# Polarfire SoC register map
Vendor: Microchip; File version: 1.0
CPU: Microchip PolarFire SoC 1.0, little endian
Registers are 32-bit, read-write, reset 0x0 unless marked. A register's access mark holds for its fields unless they carry their own. Offsets are from the block's base; [hi:lo] are bit positions; {n}, {i} and the like mark numbered series.

## EMMC_SD (part 1 of 2) — EMMC_SD Controller
Base 0x20008000
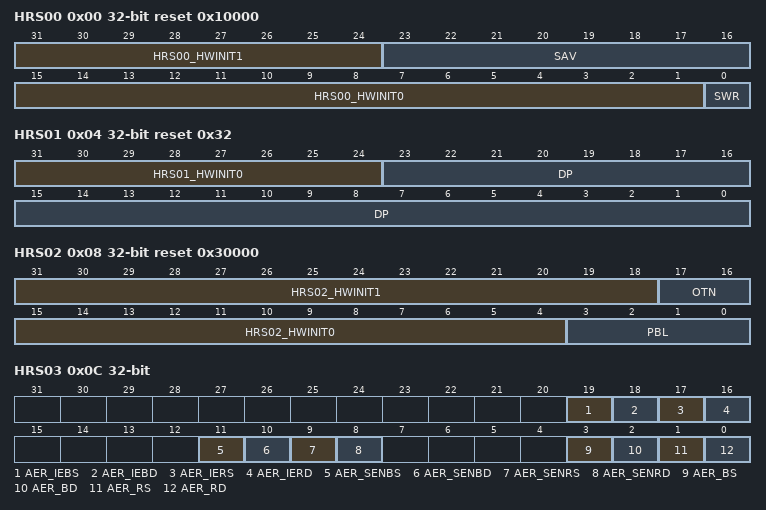
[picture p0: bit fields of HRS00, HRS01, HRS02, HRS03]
0x00 HRS00 reset 0x10000 — HRS00 - General Information Register
  [31:24] HRS00_HWINIT1 ro — HWINIT field
  [23:16] SAV ro — SAV - Slot Available This field provides a number of implemented slots. Each bit of the field is assigned to one of the slots (slot 0 is assigned to bit 16 of HRS00 register, slot 1 to bit 17, etc.). If given slot is implemented, the bit is read as 1. Otherwise, if given slot in unavailable, corresponding bit is 0. The slot 0 is always available. If slot n is implemented, the slot n-1 also is implemented. This configuration supports one slot and this field is equal to 0x01 (although the value can be altered by changing HWINIT_HRS00 value). HWINIT Field - Note this field is hardware initialized after reset and the value read back will match the IP configuration.
  [15:1] HRS00_HWINIT0 ro — HWINIT field
  [0] SWR — SWR - Software Reset When set to 1, the entire core is reset. After reset operation complete, SWR bit is automatically cleared. It takes some time to complete the requested reset operation, so the software should always poll SWR bit status, and continue the other operations only when SWR is cleared to 0. There is no difference between SWR and SRS11.SRFA software resets. Both resets the same flip-flops.
0x04 HRS01 reset 0x32 — HRS01 - Debounce Setting Register
  [31:24] HRS01_HWINIT0 ro — HWINIT field
  [23:0] DP — DP - Debounce Period Defines the number of system (clk) clock cycles used by the debounce logic, which detects card insertion and removal events. The debounce period is equal to DP * tclk, where tclk is the period of clk clock. If there is no change on s#_sdcd_n signal level for a programmed debounce period, the core logic decodes the card state as stable and triggers card_inserted or card_removed event. Typically, DP value should be chosen to obtain the period of 20ms. This register is reset to DEBOUNCE_PERIOD (HWINIT_HRS01) after reset.
0x08 HRS02 reset 0x30000 — HRS02 - Bus Setting Register
  [31:18] HRS02_HWINIT1 ro — HWINIT field
  [17:16] OTN — OTN - Number of Outstanding Transfers Specifies number of outstanding transfers on DMA (Master) interface. The number of outstadings is (OTN + 1), where OTN can be defined in range 0 to 3. This register is set to 3 after reset (i.e. 4 outstanding transfers) (HWINIT_HRS02).
  [15:4] HRS02_HWINIT0 ro — HWINIT field
  [3:0] PBL — PBL - Programmable Burst Length This field defines a maximum number of beats in DMA burst. The value can be changed when no active transfer. This register is 0 after reset. 0001b - 1 beat in burst 0010b - 2 beats in burst 0011b - 4 beats in burst 0100b - 8 bits in burst other - 16 beats in burst
0x0C HRS03 — HRS03 - AXI ERROR Responses Register These registers extend the standard set of SD-HOST interrupt statuses by information about AXI interface exceptions. The registers are divided into three groups: - Signal Enable registers allow to enable/mask signaling the Interrupt Status registers (HRS03[3:0]) on interrupt port - Status Enable registers allow to enable/disable interrupt source for each Interrupt Status separately - Interrupt Status are triggered whenever the interrupt source is detected and the Status Enable register is enabled
  [19] AER_IEBS — AER_IEBS - Signal Enable for AXI ERROR Response B channel: SLVERR 1 - interrupt enable 0 - interrupt masked
  [18] AER_IEBD — AER_IEBD - Signal Enable for AXI ERROR Response B channel: DECERR 1 - interrupt enable 0 - interrupt masked
  [17] AER_IERS — AER_IERS - Signal Enable for AXI ERROR Response R channel: SLVERR 1 - interrupt enable 0 - interrupt masked
  [16] AER_IERD — AER_IERD - Signal Enable for AXI ERROR Response R channel: DECERR 1 - interrupt enable 0 - interrupt masked
  [11] AER_SENBS — AER_SENBS - Status Enable for AXI ERROR Response B channel: SLVERR 1 - status enable 0 - status disable
  [10] AER_SENBD — AER_SENBD - Status Enable for AXI ERROR Response B channel: DECERR 1 - status enable 0 - status disable
  [9] AER_SENRS — AER_SENRS - Status Enable for AXI ERROR Response R channel: SLVERR 1 - status enable 0 - status disable
  [8] AER_SENRD — AER_SENRD - Status Enable for AXI ERROR Response R channel: DECERR 1 - status enable 0 - status disable
  [3] AER_BS — AER_BS - AXI ERROR Response B channel: SLVERR This bit is set when a SLVERR is detected on AXI Master bus in B channel (Write Response Channel).
  [2] AER_BD — AER_BD - AXI ERROR Response B channel: DECERR This bit is set when a DECERR is detected on AXI Master bus in B channel (Write Response Channel).
  [1] AER_RS — AER_RS - AXI ERROR Response R channel: SLVERR This bit is set when a SLVERR is detected on AXI Master bus in R channel (READ Response Channel).
  [0] AER_RD — AER_RD - AXI ERROR Response R channel: DECERR This bit is set when a DECERR is detected on AXI Master bus in R channel (READ Response Channel).
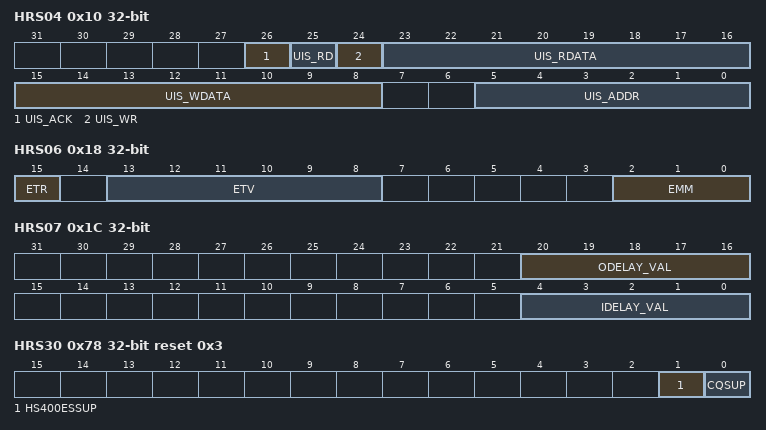
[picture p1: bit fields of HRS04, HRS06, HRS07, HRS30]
0x10 HRS04 — HRS04 - SD/eMMC PHY Registers Interface This register enables access to the SD/eMMC PHY registers. The interface behavior is described in section SD/eMMC PHY Register Intreface.
  [26] UIS_ACK ro — UIS_ACK - PHY Transaction Acknowledge This bit is set 1 when UIS_WR or UIS_RD is confirmed, so either read data is available in UIS_RDATA, or written data is already updated PHY register.
  [25] UIS_RD — UIS_RD - PHY Read Transaction Request This bit requests read transaction from PHY Register.
  [24] UIS_WR — UIS_WR - PHY Write Transaction Requests This bit requests write transaction to PHY Register.
  [23:16] UIS_RDATA ro — UIS_RDATA - PHY Read Data This field stories data read from PHY Register.
  [15:8] UIS_WDATA — UIS_WDATA - PHY Write Data This field stories data to be written to PHY Register.
  [5:0] UIS_ADDR — UIS_ADDR - PHY Register Address This filed stories address of PHY Register which is to be read of written. Refer to the Integration Manual (cdns_sd4hc_integration_manual.pdf), Table: Remapping register address to address of registers described in SD/eMMC PHY User Guide (cdns_sd_emmc_dll_phy_user_guide.pdf).
0x18 HRS06 — HRS06 - eMMC control registers
  [15] ETR — ETR - eMMC Tune Request Setting this bit 1, the tune value is updated by ETV. This bit is set 1 until the requested value is applied. The tuning command request is to be set after this bit is automatically clear to 0.
  [13:8] ETV — ETV - eMMC Tune Value This register contains value can update the tune value and in consequence sample point. The value become tune value when the ETR transits from 1 to 0.
  [2:0] EMM — EMM - eMMC Mode select This field sets eMMC mode. The mode should reflect to the eMMC device setting. If the SD card is in use, this field needs to be 0000b. 0000b - SD Card in use 0010b - SDR 0011b - DDR 0100b - HS200 0101b - HS400 0110b - HS400 Enhanced Strobe others - Legacy
0x1C HRS07 — HRS07 - IO Delay Information Register
  [20:16] ODELAY_VAL — ODELAY_VAL - Output delay value for IO. Designer should update this register with delay value of IO with appriopriate output delay. Delay is count in half of period of sdmclk. If sdmclk is working at 200MHz frequency, then 1 is 2,5 ns. This value will be used to compensate delay of DAT line when controller is READ WAIT. The sum value of IDELAY_VAL, ODELAY_VAL should be less equal 5'd20 for controller to work properly.
  [4:0] IDELAY_VAL — IDELAY_VAL - Input delay value for IO. Designer should update this register with delay value of IO with appriopriate input delay. Delay is count in half of period of sdmclk. If sdmclk is working at 200MHz frequency, then 1 is 2,5 ns. This value will be used to compensate delay of DAT line when controller is driving READ WAIT. The sum value of IDELAY_VAL, ODELAY_VAL should be less equal 5'd20 for controller to work properly.
0x78 HRS30 ro reset 0x3 — HRS30 - Host Capability Register This register states whether configurable options are available or are not available in the SD/eMMC Host Controller configuration. This register gives such information about features not been covered by the standard capability registers (SRS16-SRS18).
  [1] HS400ESSUP — High Speed 400 Enhance Strobe supported This field informs whether HS400 Enhance Strobe mode is supported (1) or is not supported (0).
  [0] CQSUP — Command Queuing supported This field informs whether Command Queuing is supported (1) or is not supported (0).
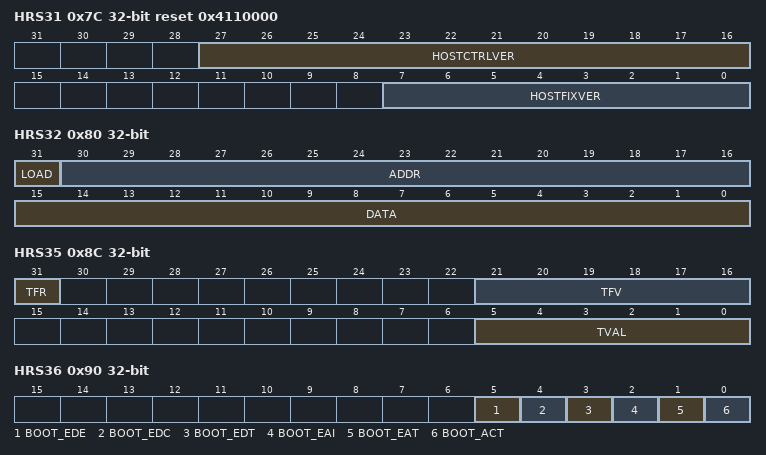
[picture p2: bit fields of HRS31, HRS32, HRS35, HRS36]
0x7C HRS31 ro reset 0x4110000 — HRS31 - Host Controller Version This register contains the host controller version number.
  [27:16] HOSTCTRLVER — Host Controller Version Release number of the Host Controller
  [7:0] HOSTFIXVER — Fix Version Number Number of the fix related to the Host Controller Version.
0x80 HRS32 — HRS32 - FSM Monitor Register
  [31] LOAD — LOAD - FSM monitor update request Setting this bit to 1 starts internal FSM monitor to load value from selected FSM. After finishing this bit will be automatically cleared by hardware and FSM status can be read.
  [30:16] ADDR — ADDR - FSM address This field selects which FSM status will be read. All available status machines are listed in Debug section of User Guide.
  [15:0] DATA ro — DATA - FSM status This register contains read FSM status. Before reading it user should select FSM address (ADDR), set LOAD bit and wait until hardware clears it.
0x84 HRS33 ro — HRS33 - Tune Status 0 Register
  [31:0] STAT0 — STAT0 - Tune status 0 After invoking UHS-I tunning procedure each bit of this register represents status of one tuning step. This field correspond to tuning steps 31-0. 0 - Step failed 1 - Step passed
0x88 HRS34 ro — HRS34 - Tune Status 1 Register
  [7:0] STAT1 — STAT1 - Tune status 1 This field is continuation of STAT0 field. Its value represents status of tuning steps 39-32.
0x8C HRS35 — HRS35 - Tune Debug Register
  [31] TFR — TFR - Tune Force Request Setting this bit 1, the tune value is updated by TFV. This bit is set 1 until the requested value is applied. The tuning command request is to be set after this bit is automatically clear to 0.
  [21:16] TFV — TFV - Tune Force Value This register contains value which can update the tune value and in consequence sample point. The new tune value becomes valid when the TFR transits from 1 to 0.
  [5:0] TVAL ro — TVAL - Tune Current Value This field represents selected value of UHS-I delay.
0x90 HRS36 ro — HRS36 - Boot Status Register
  [5] BOOT_EDE — Boot Error - End Bit Error
  [4] BOOT_EDC — Boot Error - Data CRC Error
  [3] BOOT_EDT — Boot Error - Data Timeout Error
  [2] BOOT_EAI — Boot Error - Invalid Acknowledge Error
  [1] BOOT_EAT — Boot Error - Acknowledge Timeout Error
  [0] BOOT_ACT — Boot Active Informs that the BOOT is active and the operation cannot be interfere by writing any registers.
0x94 HRS37 — HRS37 - Read block gap coefficient interface mode select
  [5:0] RGB_COEFF_IFM — RGB_COEFF_IFM - Read Block Gap Coefficient This register selects a target Read Block Coefficient. The Host Controller has a set of Read Block Coefficient registers. Each SD and eMMC speed mode has one dedicated register. While HRS38 is updated to set a Coefficient value, this register selects a target Read Block Coefficient. Following list shows the addresses to speed modes relation: 000000b - Default Speed (DS) 000001b - High Speed (HS) 001000b - UHS-I SDR12 001001b - UHS-I SDR25 001010b - UHS-I SDR50 001011b - UHS-I SDR104 001100b - UHS-I DDR50 100000b - eMMC Legacy 100001b - eMMC SDR 100010b - eMMC DDR 100011b - eMMC HS200 100100b - eMMC HS400 100101b - eMMC HS400 Enhanced Strobe
0x98 HRS38 — HRS38 - Read block gap coefficient
  [3:0] RGB_COEFF — Read block gap coefficient. Read block gap timing can be variable based on pad timing when the clock is stopped for flow control or stop at block gap purposes. When stopping the clock the host controller has default settings for each interface mode that ensures read block gap timing is met with pad delays up to 5ns (input and output path). If pad delays are longer than 5ns then the default settings can changed (increased) to ensure read block gap timing is not violated. HRS38 has a register for each interface mode and the interface mode is selected by using HRS38.
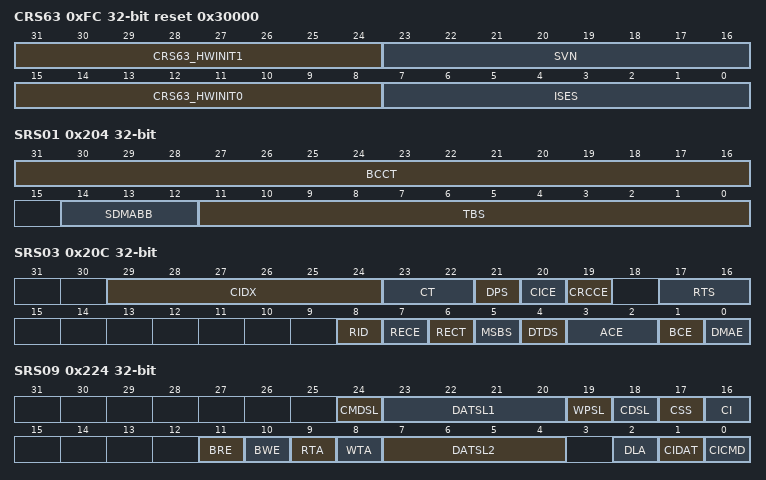
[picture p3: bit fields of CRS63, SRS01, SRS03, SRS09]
0xFC CRS63 ro reset 0x30000 — CRS63 - Host Controller Version/Slot Interrupt Status
  [31:24] CRS63_HWINIT1 — HWINIT field
  [23:16] SVN — SVN - Specification Version Number. This field identifies the Host Controller Specification Version. 0h - Version 1.00 1h - Version 2.00 2h - Version 3.00 3h - Version 4.00 4h-FFh - reserved The host is compatible with SD Host Specification Version 4.00. HWINIT Field - Note this field is hardware initialized after reset and the value read back will match the IP configuration.
  [15:8] CRS63_HWINIT0 — HWINIT field
  [7:0] ISES — ISES - Interrupt Signal For Each Slot. This field allows to determine which slot is currently signaling Interrupt/Wakeup signals. Each bit is logical OR of all Interrupts Signal and Wakeup Signal implemented in given slot. 0 - Slot 1 1 - Slot 2 ... 7 - Slot 8
0x200 SRS00 — SRS00 - SDMA System Address / Argument 2
  [31:0] SAAR — SAAR - System Address / Argument 2 This field is used as: - SDMA system memory address - Auto CMD23 Argument System Address: This register is used as base address when SDMA engine is selected (SRS03.DMAE=1 and SRS10.DMASEL=0) and SRS15.HV4E=0. When the SDMA has stopped at the SDMA block gap, writing to SAAR[31:24] resumes SDMA transfer. If the SDMA engine is stopped, value of the SAAR[31:24] register is set to the next contiguous system address of the next data position Auto CMD23 Argument: This mode is used when non-DMA or ADMA2 engine is selected or SRS15.HV4E=1. When the block count is enabled, software will set value from range 00000000h to 0000FFFFh.
0x204 SRS01 — SRS01 - Block Size / Block Count
  [31:16] BCCT — BCCT - Block Count For Current Transfer With this field, the number of data blocks can be defined for next transfer. This register is used when SRS03.BCE is set 1, otherwise it will be ignored. The value is decremented after each block transfer. When this field is set 0, no data blocks will be transferred. During data transfer read operation may return invalid value, and write operations are ignored. 0000h - no block transfer 0001h..FFFFh - 1..65535 block(s) transfer.
  [14:12] SDMABB — SDMABB - SDMA Buffer Boundary In this field, the system address boundary can be set for SDMA engine. The SDMA transfer stops crossing the address boundary and generates the DMA Interrupt (SRS12.DMAINT). After the DMA Interrupt, when the SRS15.HV4E is 0, the software should write new SDMA System Address (SRS00.SAAR / SRS22.DMASA1) in order to resume the SDMA transaction. 0 - 4k bytes address boundary 1 - 8k bytes address boundary 2 - 16k bytes address boundary 3 - 32k bytes address boundary 4 - 64k bytes address boundary 5 - 128k bytes address boundary 6 - 256k bytes address boundary 7 - 512k bytes address boundary
  [11:0] TBS — TBS - Transfer Block Size This field defines block size for block data transfers. During data transfer, read operations may return an invalid value, and write operations are ignored. The software will not set value that exceeds the physically implemented internal FIFO buffer size. The buffer size is equal to 2^FIFODEPTH, where FIFODEPTH is the generic parameter of the core. The SD/MMC (memory) uses block size up to 512 bytes. The SDIO can use up to 2048 bytes. 000h - not used 001h - 1 data block 002h - 2 data blocks 003h - 3 data blocks ... 1FFh - 511 data blocks 200h - 512 data blocks ... 800h - 2048 data blocks others - not used. Note: It is recommended for the software to use native data block size (512B) in case of multiple data block transfer (SRS03.MSBS==1). Using smaller block may cause unexpected response error when flow control is activated (i.e. SDCLK is disabled) during response transfer.
0x208 SRS02 — SRS02 - Argument 1
  [31:0] ARG1 — ARG1 - Command Argument 1 This field contains 32-bits argument for command issued by SRS03.CIDX file write.
0x20C SRS03 — SRS03 - Command/Transfer Mode
  [29:24] CIDX — CIDX - Command Index This field contains a command number (index) of the command to be sent. The index can be defined in range 00-63, which means all commands (CMD00-CMD63 and ACMD00-ACMD63) defined in related specifications are supported. Writing this filed triggers the actual command transfer. This field is to be written only when Command Inhibit CMD bit is 0 in Present State Register (SRS09.CICMD). To check the list of available commands, refer to the appropriate card/device specifications.
  [23:22] CT — CT - Command Type This field defines specific type of command. - Normal Command (0) - used by default when other command types are not intended to be used - Suspend Command (01b) - not used - Resume Command (10b) - not used - Abort Command (11b) - used when the software wants to stop the current data transfer (read or write data transfer). The read transfer ends by stopping transfer to the internal buffer. The write transfer ends with releasing DAT line to High-Z state. Then, after sending an Abort Command, the software will issue the software reset. The Suspend and Resume Mechanism is not supported by the SD Host version 4.00 and later, and the Suspend and Resume Commands will not be used.
    0=Normal; 1=Suspend; 2=Resume; 3=Abort
  [21] DPS — DPS - Data Present Select Set to 1 for commands which transfer data (i.e. read or write data using DAT line). Set to 0 for all other commands, including: - Commands using only CMD line - Commands with busy signalized on DAT[0] line (SRS03.RTS=11b)
  [20] CICE — CICE - Command Index Check Enable When set to 1, the host checks if the Command Index field in the response is equal to the SRS03.CIDX value. When 0, the check is not performed and Command Index field of the response is ignored. Recommended settings depends on response type, see following table for details: SRS03.RTS=00: 0 - No Response SRS03.RTS=01: 0 - R2 SRS03.RTS=10: 0 - R3, R4 SRS03.RTS=10: 1 - R1, R5, R6, R7 SRS03.RTS=11: 1 - R1b, R5b
  [19] CRCCE — CRCCE - Command CRC Check Enable When set to 1, the host checks if the CRC field of the response is valid. When 0, the CRC check is disabled and the CRC field of the response is ignored. The CRC check should be disabled for responses which do not contain an actual CRC value (some responses contain all 1s in place of the CRC field), and enabled for all other kinds of responses. Recommended settings depends on response type, see following table for details: SRS03.RTS=00: 0 - No Response SRS03.RTS=01: 0 - R2 SRS03.RTS=10: 0 - R3, R4 SRS03.RTS=10: 1 - R1, R5, R6, R7 SRS03.RTS=11: 1 - R1b, R5b
  [17:16] RTS — RTS - Response Type Select Defines the expected response length. 00b - no response 01b - 136-bit response 10b - 48-bit response 11b - 48-bit response with BUSY Every command implies one of the response types listed above. To check the response type corresponding to a given command, please refer to the appropriate card/device specifications.
  [8] RID — RID - Response Interrupt Disable When set to 1, the Command Complete Interrupt (SRS12.CC) will be disabled. The host will ignore the SRS13.CC_SE and behave as the SRS13.CC_SE would be 0. When set to 0, the SRS12.CC will be enabled or disabled depend on the SRS13.CC_SE bit only.
  [7] RECE — RECE - Response Error Check Enable When set 1, the host will look after R1/R5 responses. If any error will be detected in the response, the SRS12.ERSP bit is set to 1. The software will set this bit only when R1/R5 response is expected. The software will set SRS03.RID and RECE bits to 1 when the host checks R1/R5 errors. And both bits will be clear to 0, when the Software Driver will checks R1/R5 errors. On response error, the SRS12.ERSP bit (in Interrupt Status) is set 1.
  [6] RECT — RECT - Response Type R1/R5 Select R1 or R5 response type for the response content checker. Listed below error bits will be evaluated. RECT = 0, Response Type - R1 (SD Memory): bit 31 OUT_OF_RANGE bit 30 ADDRESS_ERROR bit 29 BLOCK_LEN_ERROR bit 26 WP_VIOLATION bit 25 CARD_IS_LOCKED bit 23 COM_CRC_ERROR bit 21 CARD_ECC_FAILED bit 20 CC_ERROR bit 19 ERRORRECT = 1 RECT = 1, Response Type - R5 (SDIO): bit 7 COM_CRC_ERROR bit 3 ERROR bit 1 FUNCTION_NUMBER bit 0 OUT_OF_RANGE This field is ignored when SRS03.RECE=0.
  [5] MSBS — MSBS - Multi/Single Block Select Multi-block or single-block data transfer can be selected with this field. 0 - Single-block 1 - Multi-block This field is hardware-protected by Command Inhibit DAT bit in Present State Register (SRS09.CIDAT). When CIDAT=1, all writes to this field are ignored.
  [4] DTDS — DTDS - Data Transfer Direction Select Selects direction of data transfer for commands with DPS=1. 0 - Write 1 - Read For commands with SRS03.DPS=0, this field is ignored. This field is hardware-protected by Command Inhibit DAT bit in Present State Register (SRS09.CIDAT). When CIDAT=1, all writes to this field are ignored.
  [3:2] ACE — ACE - Auto CMD Enable The field allows to send one additional command to the card/device when the command is issued. 00b - No auto command 01b - Auto CMD12 10b - Auto CMD23 11b - Reserved If Auto CMD disable (00b) is set, the host does not send any additional command. This setting will be used when auto command is not required or not intended. If Auto CMD12 (01b) is set, the host sends CMD12 (Abort) automatically when last block of multi-block transfer is completed. If Auto CMD23 (10b) is set, the host sends CMD23 (Set Block Count) automatically before issued transfer data command. An argument of this command can be set in SRS00. On any error the issued command will not be sent. This field is hardware-protected by Command Inhibit DAT bit in Present State Register (SRS09.CIDAT). When SRS09.CIDAT=1, all writes to this field are ignored.
  [1] BCE — BCE - Block Count Enable When set to 1, the SRS01.BCCT Block Count is enabled. Each transferred block automatically decrements the counter value. The multi-block transfer will end, when the counter reaches 0. So the finite transfer can not be performed with this setting. When 0, block counting is disabled, and SRS01.BCCT retains its value. The transfer will be infinite in non-DMA and SDMA modes. For ADMA mode the transfer can be infinite or finite. The finite transfer ends on reading the descriptor with END status (so the transfer length is designated by the table of descriptors). In case of infinite transfer, the software will explicitly set ABORT command type to stop transfer. This field is hardware-protected by Command Inhibit DAT bit in Present State Register (SRS09.CIDAT). When CIDAT=1, all writes to this field are ignored.
  [0] DMAE — DMAE - DMA Enable When set to 1, it enables DMA functionality. DMA can be enabled only if it is supported as indicated in the DMA Support in the SRS16.DMAS register. If DMA is not supported (due to host configuration), this bit is ignored. This field is hardware-protected by Command Inhibit DAT bit in Present State Register (SRS09.CIDAT). When SRS09.CIDAT=1, all writes to this field are ignored. Note: The ADMA2 mode uses only the finite transfer mode, i.e. this bit is to be set 1.
0x210 SRS04 ro — The SRS04 - SRS07 registers store the response returned by the card. The mapping of the actual device response and the SRS04 - SRS07 contents depends on the type of response. The type of response is determined by the RTS field (Response Type) for all user-defined commands. The separate cases are the Auto-CMD12 response (called R1b in the SD Memory Specification) and Auto-CMD23 response (called R1 in the SD Memory Specification). Auto-CMD12 and Auto-CMD23 responses are handled by the core automatically and goes to the SRS07 register regardless of the RTS value. SRS04-SRS07 relation to received response field: Auto-CMD12 resp: Response field R[39:8] - RESP3[31:0] Auto-CMD23 resp: Response field R[39:8] - RESP3[31:0] No response: RTS=00b 136-bit: RTS=01b, Response field R[127:8] - {RESP3[23:0], RESP2[31:0], RESP1[31:0], RESP0[31:0]} 48-bit: RTS=10b, Response field R[39:8] - RESP1[31:0] 48-bit with BUSY: RTS=11b, Response field R[39:8] - RESP1[31:0] Implementation note: Registers value are undefined after reset, and will be valid after response is received.
  [31:0] RESP1 — RESP1 - Response Register #1
{0x200+4i} SRS{i:02} ro (i=5..7) — Described in SRS04.
  [31:0] RESP{i-3} — RESP{i-3} - Response Register #{i-3}
0x220 SRS08 — SRS08 - Data Buffer
  [31:0] BDP — BDP - Buffer Data Port The field is to access the internal buffer (data block) in non-DMA transfer mode. 8-bit, 16-bit, or 32-bit access to SRS08 is possible with the following restrictions: - Only sequential contiguous access in Little Endian mode is possible. For example, if the software accesses BDP[7:0], then the next transfer will access BDP[15:8]. No byte skipping is allowed. - Each new block will start at the least significant byte of BDP, which is BDP[7:0]. - If the block size is not a multiple of 32-bits, and the software accesses BDP using 32-bit words, then the excess bytes of the last word are ignored. This allows the software driver to use only 32-bit data transfers regardless of the block size. - Access to the register with precaution - the FIFO pointers can be damaged when buffer is not ready or when number of accesses exceed the transfer block size (SRS01.TBS ). Following shows all transfers (byte enable variations) that are allowed on SRS08: Transfer width = 32-bit: be[3:0] = 'b1111 -> BDP[31:0] Transfer width = 16-bit: be[3:0] = 'b0011 -> BDP[15:0] be[3:0] = 'b1100 -> BDP[31:16] Transfer width = 8-bit: be[3:0] = 'b0001 -> BDP[7:0] be[3:0] = 'b0010 -> BDP[15:8] be[3:0] = 'b0100 -> BDP[23:16] be[3:0] = 'b1000 -> BDP[31:24]
0x224 SRS09 ro — SRS09 - Present State Register
  [24] CMDSL — CMDSL - CMD Line Signal Level (SD Mode only) The value is equal to the actual signal level on CMD line of the SD interface (s#_cmd_i). Is useful for debugging purposes.
  [23:20] DATSL1 — DATSL1 - DAT[3:0] Line Signal Level (SD Mode only) The value is equal to the actual signal level on DAT pins of the SD interface: SRS09.23 - s#_dat_i[3] pin level SRS09.22 - s#_dat_i[2] pin level SRS09.21 - s#_dat_i[1] pin level SRS09.20 - s#_dat_i[0] pin level
  [19] WPSL — WPSL - Write Protect Switch Pin Level The value is equal to the actual signal level on Write Protect pin of the SD interface (sdwp_s#_n). 1 - means that the write operation is enabled 0 - means that the write operations is disabled
  [18] CDSL — CDSL - Card Detect Pin Level The value is equal to the inverted signal level on Card Detect pin of the SD interface (sdsl_s#_n). 1 - means that the card is inserted 0 - means no card is inside the slot Debouncing is not performed on CDSL, therefore the use of Card Inserted (CI) bit is recommended during normal work. CDSL bit is useful only for debugging purposes.
  [17] CSS — CSS - Card State Stable Indicates if Card Detect Pin Level (CDSL) is stable. 1 - means that the CDSL value is stable 0 - means that the CDSL is not stable (during card insertion/removal or during the reset) Field is useful for debugging purposes.
  [16] CI — CI - Card Inserted Indicates if the card is inserted inside the slot. 0 - no card in slot 1 - card is inserted Unlike SRS09.CDSL, value of SRS09.CI bit is guaranteed to be stable (i.e. debouncing is performed on this bit). Use of this bit is recommended during the normal operation of host.
  [11] BRE — BRE - Buffer Read Enable This field represents data buffer (SRS08.BDP) state for read transfer in non-DMA mode. 1 - valid data can be read from the data buffer 0 - no valid data inside the data buffer After reading the entire data block, this bit changes to 0.
  [10] BWE — BWE - Buffer Write Enable This bit represents data buffer (SRS08.BDP) state for write transfer in non-DMA mode. 1 - data can be written to the data buffer 0 - data cannot be written After reading the entire data block, this changes to 0. This bit will be cleared in case of SBGR at non-DMA write transfer (even if the internal buffer is ready). The buffer must not be written after the SBGR. If the BWR was set, the only action from the S/W is to clear the interrupt status.
  [9] RTA — RTA - Read Transfer Active (SD Mode only) Indicates the status of the read data transfer. 0 - no data read transfer in progress 1 - data read transfer in progress Bit is set 1 after sending the read command, or after restarting the read transfer by the Continue Request (SRS10.CREQ). Bit is set 0 by the hardware after the last block of the read transfer, or after stopping the read transfer by the Stop at Block Gap Request (SRS10.SBGR). In both cases, the entire data is to be read by the system from the internal data buffer before setting this bit to 0. In other words, SRS09.RTA=0 means that the entire data is already transferred to the system, and internal data buffer is empty.
  [8] WTA — WTA - Write Transfer Active (SD Mode only) Indicates the status of the write data transfer. 0 - no data write transfer in progress 1 - data write transfer in progress Bit is set 1 after sending the write command, or after restarting the write transfer by the Continue Request (SRS10.CREQ). Bit is set 0 by the hardware after the last block of the write transfer, or after stopping the write transfer by the Stop at Block Gap Request (SRS10.SBGR). In both cases, the entire data has to be transferred to the card from the internal data buffer before setting this bit to 0. In other words, WTA=0 means that the entire data is already transferred to the card, and CRC response for the last data block is already received.
  [7:4] DATSL2 — DATSL2 - DAT[7:4] Line Signal Level (SD Mode only) Field can be used to monitor DAT lines in range 7-4. The value is equal to the actual signal level on DAT pins of the SD interface: SFR9.7 - dat7_i_pin level SFR9.6 - dat6_i_pin level SFR9.5 - dat5_i_pin level SFR9.4 - dat4_i_pin level
  [2] DLA — DLA - DAT Line Active (SD Mode only) Indicates if the DAT lines of SD interface are currently in use. 1 - DAT lines are active (in use) 0 - DAT lines are released (not in use) This bit set to 1, when Read or Write Transfer bits are active (SRS09.RTA=1 or SRS09.WTA=1), or if the card indicates busy state on the DAT lines. The card can become busy immediately after the write operation, or after command which requires response with busy. Falling edge of this bit (change from 1 to 0) directly triggers Transfer Complete Interrupt (SRS12.TC).
  [1] CIDAT — CIDAT - Command Inhibit DAT (SD Mode only) Indicates if the host can issue a command which uses DAT line. Commands which use DAT line include write and read data commands and commands with busy response. 1 - command using DAT line cannot be sent 0 - command using DAT line can be sent When CIDAT=1 then the SRS03[15:0] is write-protected. The software can write SRS03[15:0] only when CIDAT=0.
  [0] CICMD — CICMD - Command Inhibit CMD Indicates if the host can issue a command. 0 - command can be sent 1 - command cannot be sent If this bit is 0, indicates the CMD line is not in use and the Host Controller can issue an SD command using the CMD line. This bit is set immediately after the CI is written, indicating start of command transmission. This bit is cleared when the command response is received. Even if the Command Inhibit DAT is set to 1, commands using only the CMD line can be issued if the Command Inhibit CMD is 0. Change from 1 to 0 directly triggers Command Complete Interrupt (SRS12.CC).
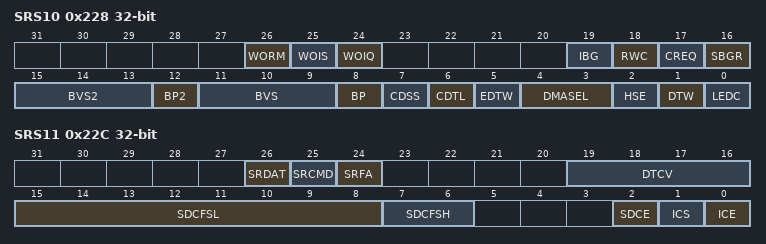
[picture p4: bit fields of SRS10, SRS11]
0x228 SRS10 — SRS10 - Host Control 1 (General / Power / Block-Gap / Wake-Up)
  [26] WORM — WORM - Wakeup Event Enable On SD Card Removal When set to 1, enables wake-up event via Card Removal assertion in the SRS12.CR register.
  [25] WOIS — WOIS - Wake-Up Event Enable On Card Inserted When set to 1, enables wake-up event via Card Insertion assertion in the SRS12.CIN register.
  [24] WOIQ — WOIQ - Wakeup Event Enable On Card Interrupt When set to 1, enables wake-up event via Card Interrupt assertion in the SRS12.CINT
  [19] IBG — IBG - Interrupt At Block Gap (SD Mode only) When set to 1, enables interrupt detection at the block gap for a multiple block transfer. This bit is valid only in SD4 mode. If the SD card cannot signal an interrupt during a multiple block transfer, this bit should be set to 0. This field is ignored in UHS-II mode.
  [18] RWC — RWC - Read-Wait Control (SD Mode only) When set to 1, enables Read Wait control. The Read Wait function is optional for SDIO cards. If the card does not support read wait, this bit would never be set to 1; otherwise, DAT line conflict may occur. This field is ignored in UHS-II mode.
  [17] CREQ — CR - Continue Request When set to 1, restarts the transfer previously stopped using the Stop At Block Gap. The software will set SRS10.SBGR (Stop At Block Gap) bit to 0 before setting the (CR) Continue Request. When SRS10.SBGR=1, then all write operations to Continue Request are ignored. Clearing SRS10.SBGR can be done before or simultaneously with writing the CR. Continue Request bit is cleared automatically by the host when SRS09.DLA (Dat Line Active) changes from 0 to 1, indicating the actual restart of the transfer.
  [16] SBGR — SBGR - Stop At Block Gap Request When set to 1, orders the stop executing read and write transaction at the next possible block gap for non-DMA, SDMA and ADMA transfers. The software will maintain SBGR=1 until the current transfer is complete (typically by waiting for - Transfer Complete bit). After Transfer Complete event, the software will set SBGR back to 0. In case of the read transfer, the host stops after the next data block received from the card. This uses the Read-Wait mechanism if it is enabled by SRS10.RWC, or stops the card clock (sdclk_s#) if Read-Wait is disabled. In the case of the write transfer, host stops after the last block written to the data buffer. The host sends all data already written to the internal data buffer before stopping the transfer. In case of stopping non-DMA write transfer, the software will set this bit only at block gap ( block unit (SD mode)).
  [15:13] BVS2 — BVS2 - SD Bus Voltage Select for VDD2 The field is used to configure VDD2 voltage level. The state of this field directly drives s#_bus_volt port of the core. 000b - VDD2 is not supported 001b-011b - Reserved 100b - Reserved for 1.2V 101b - 1.8V (1.8V VDD Support in Capability registers need to be set) 110b-111b - Not used
  [12] BP2 — BP2 - SD Bus Power for VDD2 This bit is used to enable (1) or disable (0) VDD2 supply. The state of this bit directly drives s#_bus_pow2 port of the core. The field is ignored in legacy mode.
  [11:9] BVS — BVS - SD Bus Voltage Select This field is used to configure VDD1 voltage level.The state of this field directly drives s#_bus_volt2 port of the core. 000b-100b - Reserved 101b - 1.8V (typical) for embedded 110b - 3.0V (typical) 111b - 3.3V (typical) others - Reserved.
  [8] BP — BP - SD Bus Power for VDD1 When set to 1, the VDD1 voltage is supplied to card/device. The state of this bit directly drives s#_bus_pow port of the core. Setting bit to 0 cause that host stops driving SDCLK, CMD/DAT lines. If the device is connected to the host, lines go low before disabling VDD1. The host will set this bit automatically to 0 when card is removed from the slot (i.e. after high to low transition on s#_sdcd_n pin). This is to provide the hot removal support.
  [7] CDSS — CDSS - Card Detect Signal Selection A card detection mechanism will base on either s#_sdcd_n port or register value. 0 - s#_sdcd_n pin (normal mode) 1 - CDTL(SRS10.6) bit (testing mode)
  [6] CDTL — CDTL - Card Detect Test Level Designates card insertion status when SRS10.CDSS=1. Bit provided for test purposes. 0 - no card 1 - card inserted
  [5] EDTW — EDTW - Extended Data Transfer Width This bit is to enable/disable 8-bit DAT bus width mode. 0 - bus width selected by SRS10.DTW 1 - 8-bit mode enabled
  [4:3] DMASEL — DMASEL - DMA Select In this field the DMA mode can be selected. The field behaviour depends on the Host Controller Compatibility bit (SRS15.HV4E). Host Controller version 3.00 compatible mode (SRS15.HV4E=0) 00b - SDMA mode 01b - Reserved 10b - ADMA2 (32-bit Address) 11b - ADMA2 (64-bit Address) Host Controller version 4.00 compatibility mode (SRS15.HV4E=1) 00b - SDMA mode 01b - Not Used 10b - ADMA2 mode 11b - Reserved The ADMA2 address bus width is configured by 64-bit Addressing bit in Host Controller 2 register when SRS15.HV4E=1.
  [2] HSE — HSE - High Speed Enable (SD mode only) Selects operating mode to Default Speed (HSE=0) or High Speed (HSE=1). The maximum SD clock frequency is defined as 0-25MHz in the default speed mode, and 0-50MHz in the High Speed mode.
  [1] DTW — DTW - Data Transfer Width (SD mode only) Bit used to configure DAT bus width to 1 or 4. 0 - 1-bit mode 1 - 4-bit mode This bit is ignored when the SRS10.EDTW is set 1 (8-bit mode selected).
  [0] LEDC — LEDC - LED Control State of this bit directly drives led port of the host in order to control the external LED diode. LEDC=1 will switch LED on, while LEDC=0 will switch it off. The software will switch LED on to caution the user not to remove the card while the transfer is in progress.
0x22C SRS11 — SRS11 - Host Control 2 (Clock, Timeout, Reset)
  [26] SRDAT — SRDAT - Software Reset For DAT Line (SD Mode only) When set to 1, resets the logic related to the data path, including data buffers and the DMA logic. The following registers and bits are cleared: SRS08 register: - Buffer SRS09 register: - Buffer Read Enable - Buffer Write Enable - Read Transfer Active - Write Transfer Active - DAT Line Active - Command Inhibit DATSRS10 register: - Continue Request - Stop At Block Gap Request SRS12 register: - Buffer Read Ready - Buffer Write Ready - DMA Interrupt - Block Gap Event - Transfer Complete After completing the reset operation, SRS11.SRDAT bit is automatically cleared. It takes some time to complete the reset operation, so the software will wait until SRS11.SRDAT=0, and continue the other operations only when SRS11.SRDAT=0.
  [25] SRCMD — SRCMD - Software Reset For CMD Line (SD Mode only) When set to 1, resets the logic related to the command generation and response checking. The following registers and bits are cleared: - SRS09 register: Command Inhibit CMD - SRS12 register: Command Complete After completing the reset operation, SRS11.SRCMD bit is automatically cleared. It takes some time to complete the reset operation, so the software will wait until SRCMD=0, and continue the other operations only when SRS11.SRCMD=0.
  [24] SRFA — SRFA - Software Reset For All When set to 1, the entire slot is reset.After completing the reset operation, SRFA bit is automatically cleared. It takes some time to complete the reset operation, so the software will wait until SRFA=0, and continue the other operations only when SRFA=0. Additionally, after SRFA, software should reset and reinitialize card inserted to the slot. SD Card Power may be enabled 1 ms after this bit is cleared to ensure SD Card has been reset properly.
  [19:16] DTCV — DTCV - Data Timeout Counter Value This value determines the interval by which DAT line timeouts are detected. The interval can be computed as below: 1111b - Reserved 1110b - t_sdmclk*2^(27+2) 1101b - t_sdmclk*2^(26+2) ... 0001b - t_sdmclk*2^(14+2) 0000b - t_sdmclk*2^(13+2) Where t_sdmclk is the sdmclk clock periodRefer to the Data Timeout Error (SRS12.EDT) register for information on factors which generate data timeouts.
  [15:8] SDCFSL — SDCFSL - SDCLK Frequency Select (lower part) This register and SRS11.SDCFSH are used to calculate frequency of SDCLK clock. The SDCLK frequency is calculated with following expressions: - sdclk = sdmclk; when (N=0) - sdclk = sdmclk/2N; when (N>0) Variable N is concatenation of SRS11.SDCFSH and SRS11.SDCFSL. The value of SDCFSL, SDCFSH registers can be changed only when SRS11.SDCE (SD Clock Enable)=0.
  [7:6] SDCFSH — SDCFSH - SDCLK Frequency Select (higher part) This register is an extension to SDCFSL.
  [2] SDCE — SDCE - SD Clock Enable When set to 1, SDCLK clock is enabled. When cleared to 0, SDCLK clock is stopped. The host clears SDCE automatically when card is removed from the slot (i.e. after the high to low transition on s#_sdcd_n pin). The SDCLK clock should be stopped by the software when changing the clock divider (i.e. SDCE bit will be cleared before writing SRS11.SDCFSL, SRS11.SDCFSH).
  [1] ICS ro — ICS - Internal Clock Stable When read as 1, indicates that the clock on sdmclk pin of the host is stable after setting ICE to 1. When read as 0, indicates that the clock is not stable yet (for example the external PLL that generates the clock is not yet locked). The value of ICS is equal to the actual signal level on ics pin of the host. The user will connect ics to the external PLL if required. Otherwise, ics should be connected directly to the ice output of the host.
  [0] ICE — ICE - Internal Clock Enable This field is designated to controls (enable/disable) external clock generator (e.g. PLL). The ICE bits of every slot are logically OR-ed together and then drive the ice pin. It means, the ice pin is 0 only when ICE in 0 for every slot implemented inside the host. The ice pin is 1 if at least one of the ICE bits is set to 1. When set to 0, the clock on sdmclk pin can be stopped externally. If the sdmclk is stopped, then host goes to a very low power state. The hosts registers are still operable (read and written operation are valid) even if the clock on sdmclk is stopped. Setting of the ICE bit does not affect card detection. It means, the card detection works even if the clock on sdmclk is stopped.
